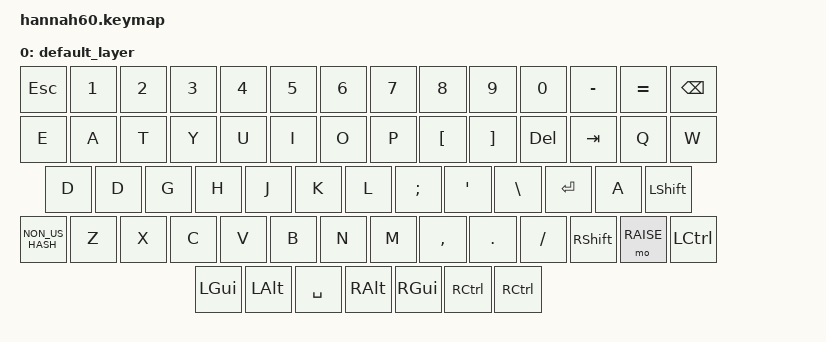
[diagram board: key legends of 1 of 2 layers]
/*
 * Copyright (c) 2020 The ZMK Contributors
 *
 * SPDX-License-Identifier: MIT
 */
/* THIS FILE WAS GENERATED!
 *
 * This file was generated automatically. You may or may not want to
 * edit it directly.
 */

#include <behaviors.dtsi>
#include <dt-bindings/zmk/keys.h>

/ {
    keymap {
        compatible = "zmk,keymap";

        default_layer {
            bindings = <
         &kp ESC    &kp N1     &kp N2    &kp N3    &kp N4     &kp N5     &kp N6  &kp N7     &kp N8    &kp N9    &kp N0  &kp MINUS  &kp EQUAL   &kp BSPC
                     &kp E      &kp A     &kp T     &kp Y      &kp U      &kp I   &kp O      &kp P  &kp LBKT  &kp RBKT    &kp DEL    &kp TAB      &kp Q   &kp W
                     &kp D      &kp D     &kp G     &kp H      &kp J      &kp K   &kp L   &kp SEMI   &kp SQT  &kp BSLH    &kp RET      &kp A  &kp LSHFT
 &kp NON_US_HASH     &kp Z      &kp X     &kp C     &kp V      &kp B      &kp N   &kp M  &kp COMMA   &kp DOT  &kp FSLH  &kp RSHFT  &mo RAISE  &kp LCTRL
        &kp LGUI  &kp LALT  &kp SPACE  &kp RALT  &kp RGUI  &kp RCTRL  &kp RCTRL
            >;
        };

        layer_lower {
            bindings = <
 &trans       &kp F1  &kp F2   &kp F3  &kp F4  &kp F5  &kp F6  &kp F7  &kp F8  &kp F9  &kp F10  &kp F11   &kp F12  &trans
         &bootloader  &trans  &kp INS  &trans  &trans  &trans  &trans  &trans  &trans   &trans   &trans    &trans  &trans  &trans
           &kp RIGHT  &trans   &trans  &trans  &trans  &trans  &trans  &trans  &trans   &trans   &trans  &kp LEFT  &trans
 &trans       &trans  &trans   &trans  &trans  &trans  &trans  &trans  &trans  &trans   &trans   &trans    &trans  &trans
 &trans       &trans  &trans   &trans  &trans  &trans
            >;
        };
    };
};
